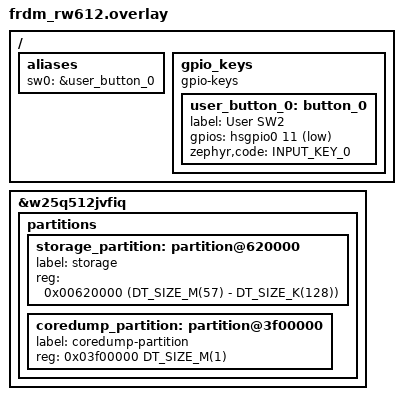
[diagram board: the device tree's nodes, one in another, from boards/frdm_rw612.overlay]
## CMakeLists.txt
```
cmake_minimum_required(VERSION 3.20.0)

# Board overlays use Zephyr 4.4 layouts; extend them for Zephyr 4.5 and newer.
find_package(Zephyr REQUIRED HINTS $ENV{ZEPHYR_BASE} COMPONENTS version)
if (KERNEL_VERSION_STRING VERSION_GREATER_EQUAL "4.5.0")
  set(coredump_board "${BOARD}")
  if (NOT coredump_board)
    set(coredump_board "$ENV{BOARD}")
  endif ()
  string(REGEX REPLACE "@[^/]*" "" coredump_board "${coredump_board}")
  string(REPLACE "/" "_" coredump_board "${coredump_board}")
  set(coredump_partition_overlay
      "${CMAKE_CURRENT_SOURCE_DIR}/boards/zephyr-4.5/${coredump_board}.overlay")
  if (EXISTS "${coredump_partition_overlay}")
    list(APPEND EXTRA_DTC_OVERLAY_FILE "${coredump_partition_overlay}")
  endif ()
endif ()

find_package(Zephyr REQUIRED HINTS $ENV{ZEPHYR_BASE})
project(spotflow_ble)

target_sources(app PRIVATE src/main.c)
```

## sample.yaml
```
sample:
  name: Spotflow BLE sample
tests:
  sample.spotflow.ble:
    integration_platforms:
      - siwx917_dk2605a
    platform_allow:
      - siwx917_dk2605a
    tags:
      - bluetooth
      - spotflow
    harness: bluetooth
```

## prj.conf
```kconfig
CONFIG_SPOTFLOW=y
CONFIG_SPOTFLOW_TRANSPORT_BLE=y
CONFIG_SPOTFLOW_COREDUMPS=y
CONFIG_SPOTFLOW_LOG_BACKEND=y
CONFIG_SPOTFLOW_METRICS=y
CONFIG_SPOTFLOW_METRICS_HEARTBEAT_INTERVAL=10
CONFIG_SPOTFLOW_METRICS_SYSTEM=y
# limit the the number of threads to avoid overloading the ble transport with
# metric with too many dimensions
CONFIG_SPOTFLOW_METRICS_SYSTEM_STACK_MAX_THREADS=16

CONFIG_BT=y
CONFIG_BT_PERIPHERAL=y
CONFIG_BT_DEVICE_NAME="Spotflow BLE device"
CONFIG_BT_DEVICE_APPEARANCE=0

CONFIG_GPIO=y

CONFIG_SPOTFLOW_DEVICE_ID="testing_device"

CONFIG_LOG=y
CONFIG_LOG_DEFAULT_LEVEL=3
CONFIG_LOG_BACKEND_UART=y
CONFIG_LOG_MAX_LEVEL=4
CONFIG_PRINTK=y
CONFIG_CONSOLE=y
CONFIG_UART_CONSOLE=y
CONFIG_MAIN_STACK_SIZE=2048
```

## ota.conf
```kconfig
# Add with EXTRA_CONF_FILE for OTA-capable boards. Keep the default BLE sample
# usable on devices without persistent storage or firmware-update support.
CONFIG_SPOTFLOW_OTA=y
# Demonstration only: an unattended browser test can connect without pairing.
# Production OTA enables encryption by default; configure trusted pairing there.
CONFIG_SPOTFLOW_BLE_REQUIRE_ENCRYPTION=n
CONFIG_SETTINGS=y
CONFIG_NVS=y
CONFIG_SETTINGS_NVS=y
```

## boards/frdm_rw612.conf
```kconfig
CONFIG_BT_DEVICE_NAME="Spotflow NXP"
CONFIG_SPOTFLOW_DEVICE_ID="testing_device_nxp"

CONFIG_DEBUG_COREDUMP_THREADS_METADATA=y
CONFIG_DEBUG_COREDUMP_MEMORY_DUMP_THREADS=y
```

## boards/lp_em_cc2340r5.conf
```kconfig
# CC2340R5 has only 36 KiB of SRAM, so this board uses the BLE transport with
# deliberately small queues and buffers. Keep the generic prj.conf useful for
# larger boards and put the CC2340R5 tradeoffs here.

# This sample uses logs, and coredumps with tightly bounded buffers.
# Metrics can be enabled if the application needs them, but they are disabled by default to
# save RAM. The sample does not use Spotflow Settings, so the default is disabled.

CONFIG_BT_DEVICE_NAME="Spotflow Texas Instruments"
CONFIG_SPOTFLOW_DEVICE_ID="ti_cc2340r5"

# This sample does not add session labels. The run ID and build ID fit in the
# minimum BLE metadata workspace.
CONFIG_SPOTFLOW_SESSION_METADATA_BUFFER_SIZE=64

# The common sample already enables Spotflow BLE logging. Keep these explicit so
# this board profile remains self-contained if prj.conf changes later.
CONFIG_SPOTFLOW=y
CONFIG_SPOTFLOW_TRANSPORT_BLE=y
CONFIG_SPOTFLOW_LOG_BACKEND=y
CONFIG_SPOTFLOW_COREDUMPS=y

# The TI CC23x0 downstream SoC reboot hook does not implement SYS_REBOOT_COLD.
# Use warm reboot so coredump-triggered fatal errors reset instead of spinning.
CONFIG_SPOTFLOW_COREDUMPS_REBOOT_WARM=y

# Enable the metrics supported by this BLE-only target. Network metrics require
# Zephyr networking, and this TI downstream does not provide CPU_LOAD.
CONFIG_SPOTFLOW_METRICS=n
# CONFIG_SPOTFLOW_METRICS=y
# CONFIG_SPOTFLOW_METRICS_SYSTEM=y
# CONFIG_SPOTFLOW_METRICS_SYSTEM_HEAP=y
# CONFIG_SPOTFLOW_METRICS_SYSTEM_NETWORK=n
# CONFIG_SPOTFLOW_METRICS_SYSTEM_CPU=n
# CONFIG_SPOTFLOW_METRICS_SYSTEM_CONNECTION=y
# CONFIG_SPOTFLOW_METRICS_SYSTEM_RESET_CAUSE=y
# CONFIG_SPOTFLOW_METRICS_SYSTEM_STACK=y
# CONFIG_SPOTFLOW_METRICS_SYSTEM_STACK_ALL_THREADS=n
# CONFIG_SPOTFLOW_METRICS_SYSTEM_STACK_MAX_THREADS=2
# CONFIG_SPOTFLOW_METRICS_SYSTEM_COLLECTION_INTERVAL=30
# CONFIG_SPOTFLOW_METRICS_SYSTEM_AGGREGATION_INTERVAL=60

# Six system metrics, the sample counter, battery level, and accelerometer
# magnitude exactly fill the registry. All current metric names, including their
# terminators, fit in 32 bytes.
# CONFIG_SPOTFLOW_METRICS_MAX_REGISTERED=10
# CONFIG_SPOTFLOW_METRICS_MAX_NAME_LENGTH=32
# CONFIG_SPOTFLOW_METRICS_MAX_LABELS_PER_METRIC=1
# CONFIG_SPOTFLOW_METRICS_QUEUE_SIZE=4
# CONFIG_SPOTFLOW_METRICS_CBOR_BUFFER_SIZE=256
# CONFIG_SPOTFLOW_METRICS_HEARTBEAT=y
# CONFIG_SPOTFLOW_METRICS_HEARTBEAT_INTERVAL=60
# CONFIG_HEAP_MEM_POOL_ADD_SIZE_SPOTFLOW_METRICS=4096
# CONFIG_HEAP_MEM_POOL_ADD_SIZE_SPOTFLOW_METRICS_SYSTEM=8192

# Persisted cloud configuration remains disabled; Settings/NVS needs its own
# storage budget.
CONFIG_SPOTFLOW_SETTINGS=n

# Spotflow BLE session metadata and coredump IDs use sys_rand32_get(). The board
# disables entropy by default, so enable the CC23x0 entropy source here.
CONFIG_ENTROPY_GENERATOR=y

# This BLE-only sample does not need TLS. The board default enables MbedTLS, but
# TinyCrypt is already present through Bluetooth and is enough for CTR-DRBG.
CONFIG_MBEDTLS=n
CONFIG_CTR_DRBG_CSPRNG_GENERATOR=y

# The CC23x0 entropy driver allocates the radio-noise buffer from the system heap
# during startup. 256 words is the driver-enforced minimum and 64 bytes is enough
# to seed CTR-DRBG for this sample. Increase back to 512/128 if more subsystems
# start consuming raw entropy directly.
CONFIG_ENTROPY_CC23X0_NOISE_INPUT_WORD_LENGTH=256
CONFIG_ENTROPY_CC23X0_ENTROPY_BYTE_LENGTH=64

# The entropy driver's hidden heap minimum is fixed at 3072 bytes even when the
# noise buffer is reduced. Right-size the shared system heap explicitly: enough
# for the 1024-byte startup entropy allocation plus Spotflow's small runtime
# queues. Increase this first if k_malloc failures appear.
CONFIG_HEAP_MEM_POOL_SIZE=4096
CONFIG_HEAP_MEM_POOL_IGNORE_MIN=y

# The Bluetooth host PRNG pulls in extra TinyCrypt HMAC/SHA state. With SMP,
# privacy and bonding disabled, Zephyr's CTR-DRBG-backed random API is enough.
CONFIG_BT_HOST_CRYPTO_PRNG=n

# Keep UART logs for bring-up/debugging. Spotflow still sends logs over BLE; the
# UART backend only adds local visibility. If RAM becomes critical, reduce log
# levels or buffers before disabling UART.
CONFIG_LOG_BACKEND_UART=y
CONFIG_LOG_MODE_DEFERRED=y
CONFIG_LOG_DEFAULT_LEVEL=3
CONFIG_LOG_MAX_LEVEL=3
CONFIG_LOG_BUFFER_SIZE=256
CONFIG_LOG_PROCESS_THREAD_STACK_SIZE=640

# The sample main thread configures GPIO, reports one metric, and emits logs. A
# separate 640-byte thread reports generated battery and accelerometer metrics.
CONFIG_MAIN_STACK_SIZE=896

# The Spotflow processor only runs BLE framing and queue draining, not TLS.
CONFIG_SPOTFLOW_PROCESSING_THREAD_STACK_SIZE=1152

# Two queued Spotflow log messages is enough to absorb short bursts while keeping
# heap usage bounded. Increase to 4 if normal operation drops logs; decrease to 1
# only if occasional log loss is acceptable and RAM is still tight.
CONFIG_SPOTFLOW_LOG_BACKEND_QUEUE_SIZE=2
CONFIG_HEAP_MEM_POOL_ADD_SIZE_SPOTFLOW_LOGGING=512

# Keep individual log records small. The sample still sends normal short logs,
# but long lines are dropped/truncated by Spotflow rather than consuming RAM.
# 96/192 can be lowered to 64/160 for very short messages, or raised to 128/256
# if real application messages need it.
CONFIG_SPOTFLOW_LOG_BUFFER_SIZE=96
CONFIG_SPOTFLOW_CBOR_LOG_MAX_LEN=192
CONFIG_SPOTFLOW_LOG_INCLUDE_BODY_TEMPLATE=n

# Send INFO/WARNING/ERROR records to Spotflow by default. Set to 2 to send only
# warnings/errors if BLE throughput or heap pressure becomes a problem.
CONFIG_SPOTFLOW_DEFAULT_SENT_LOG_LEVEL=3
CONFIG_SPOTFLOW_MODULE_DEFAULT_LOG_LEVEL=2
CONFIG_SPOTFLOW_LOGS_PROCESSING_LOG_LEVEL=2
CONFIG_SPOTFLOW_COREDUMPS_PROCESSING_LOG_LEVEL=2

# Full RAM dumps do not fit comfortably on this device. Minimal coredumps keep
# the fault context and current stack only, which fits the small flash partition
# and is the practical option for this board.
CONFIG_DEBUG_COREDUMP_MEMORY_DUMP_MIN=y
CONFIG_SPOTFLOW_COREDUMPS_THREAD_STACK_SIZE=640

# 128-byte chunks minimize heap and static RAM. Upload is slower because BLE has
# more fragments, but reliability on 36 KiB SRAM is better than using 512/1024.
CONFIG_SPOTFLOW_COREDUMPS_CHUNK_SIZE=128
CONFIG_SPOTFLOW_COREDUMPS_BACKEND_QUEUE_SIZE=1
CONFIG_HEAP_MEM_POOL_ADD_SIZE_SPOTFLOW_COREDUMPS=512

# Use the minimum ATT MTU and ACL buffer sizes. Spotflow BLE framing fragments
# larger CBOR messages, so this saves RAM at the cost of throughput.
CONFIG_BT_L2CAP_TX_MTU=23
CONFIG_BT_BUF_ACL_TX_SIZE=27
CONFIG_BT_BUF_ACL_RX_SIZE=27
CONFIG_BT_BUF_ACL_TX_COUNT=3
CONFIG_BT_BUF_ACL_RX_COUNT=2
CONFIG_BT_L2CAP_TX_BUF_COUNT=3
CONFIG_BT_ATT_TX_COUNT=3
CONFIG_BT_CONN_TX_MAX=3

# Trim Bluetooth host features that are not needed by the Spotflow GATT service.
# Re-enable SMP/privacy/settings only if the gateway requires pairing/bonding.
CONFIG_BT_SMP=n
CONFIG_BT_GATT_SERVICE_CHANGED=n
CONFIG_BT_GATT_CACHING=n
CONFIG_BT_PHY_UPDATE=n
CONFIG_BT_DATA_LEN_UPDATE=n

# Keep HCI event/command buffers near their documented minimums. EVT count 3 is
# a small safety margin over the minimum 2; reducing to 2 is possible if measured.
CONFIG_BT_BUF_EVT_RX_SIZE=68
CONFIG_BT_BUF_EVT_RX_COUNT=3
CONFIG_BT_BUF_EVT_DISCARDABLE_COUNT=1
CONFIG_BT_BUF_CMD_TX_SIZE=65

# Enable stack measurement helpers while validating this tight RAM profile. They
# can be disabled for production if the extra diagnostics are not wanted.
CONFIG_THREAD_NAME=y
CONFIG_INIT_STACKS=y
CONFIG_STACK_SENTINEL=y
CONFIG_STACK_USAGE=y

# TI runs Bluetooth RX callbacks on sysworkq and recommends at least 1200 bytes.
CONFIG_SYSTEM_WORKQUEUE_STACK_SIZE=1280
CONFIG_ISR_STACK_SIZE=1536
```

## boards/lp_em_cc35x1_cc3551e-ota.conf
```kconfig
CONFIG_CC35XXE_FWU=y
CONFIG_CC35XXE_GENERATE_FLASH_MAP_CONFIG=y
CONFIG_CC35XXE_FLASH_PROFILE_IS25WJ032F=y
CONFIG_CC35XXE_VENDOR_IMAGE_VERSION="0.0.1.0"
CONFIG_SPOTFLOW_OTA_AUTO_HANDLE_MAIN_FIRMWARE=y
CONFIG_SPOTFLOW_OTA_MAIN_FIRMWARE_PSA_FWU=y
CONFIG_MBEDTLS_PSA_CRYPTO_EXTERNAL_RNG=y
CONFIG_CRYPTO=y
CONFIG_CRYPTO_TI_CC35XX=y
# Keep the legacy EC entry points used by TI's radio library when SMP is enabled.
CONFIG_MBEDTLS_PSA_P256M_DRIVER_ENABLED=n
```

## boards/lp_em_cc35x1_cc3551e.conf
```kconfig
CONFIG_BT_DEVICE_NAME="Spotflow Texas Instruments"
CONFIG_SPOTFLOW_DEVICE_ID="ti_cc35x1_cc3551e"

# TI's combined CC35x1 radio driver routes Bluetooth through the Wi-Fi host
# stack, whose Kconfig selections require Zephyr networking to be enabled.
CONFIG_NETWORKING=y
CONFIG_NET_L2_ETHERNET=y

# Absorb bursts from the CC35x1 driver without exhausting Zephyr's RX pools.
CONFIG_NET_PKT_RX_COUNT=32
CONFIG_NET_BUF_RX_COUNT=64

# Matches TI's CC35x1 Bluetooth peripheral reference configuration:
# zephyr/samples/bluetooth/peripheral/boards/lp_em_cc35x1_cc3551e.conf
CONFIG_BT_GATT_CACHING=n
CONFIG_BT_PHY_UPDATE=n
CONFIG_HEAP_MEM_POOL_SIZE=81920
CONFIG_MAIN_STACK_SIZE=61440
CONFIG_NET_TX_STACK_SIZE=2048
CONFIG_NET_RX_STACK_SIZE=2048
CONFIG_DYNAMIC_THREAD_POOL_SIZE=3
CONFIG_DYNAMIC_THREAD_STACK_SIZE=8192

# A full 1 MiB RAM dump cannot fit in the board's application storage area.
CONFIG_DEBUG_COREDUMP_MEMORY_DUMP_MIN=y
```

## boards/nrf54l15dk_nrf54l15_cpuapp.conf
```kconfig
CONFIG_BT_DEVICE_NAME="Spotflow nRF54L15"
CONFIG_SPOTFLOW_DEVICE_ID="testing_device_nrf54l15"

# Keep logs and metrics in RRAM while no gateway is connected
CONFIG_SPOTFLOW_PERSISTENT_BUFFER=y
# FCB needs write blocks of at most 8 bytes; with the RRAMC write buffer disabled, RRAM accepts
# 32-bit writes (see write-block-size in nrf54l15dk_nrf54l15_cpuapp.overlay)
CONFIG_NRF_RRAM_WRITE_BUFFER_SIZE=0

CONFIG_DEBUG_COREDUMP_THREADS_METADATA=y
CONFIG_DEBUG_COREDUMP_MEMORY_DUMP_THREADS=y
```

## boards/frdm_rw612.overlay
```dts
 /* GPIO not available in 4.1.0, adding based on commit
 * https://github.com/zephyrproject-rtos/zephyr/commit/2df6b7fd2dea95105b3598c41fecbd7089fab080
 */
#include <zephyr/dt-bindings/input/input-event-codes.h>
/ {
	aliases {
		/* make an alias so we can refer to "sw0" in code */
		sw0 = &user_button_0;
	};

	gpio_keys {
		compatible = "gpio-keys";

		user_button_0: button_0 {
			label = "User SW2";
			gpios = <&hsgpio0 11 (GPIO_ACTIVE_LOW | GPIO_PULL_UP)>;
			zephyr,code = <INPUT_KEY_0>;
			status = "okay";
		};
	};
};

/* External flash chip - Winbond */
&w25q512jvfiq {
	partitions {
		/* Reducing size by 1 MB to leave space for coredump */
		storage_partition: partition@620000 {
			label = "storage";
			reg = <0x00620000 (DT_SIZE_M(57) - DT_SIZE_K(128))>;
		};

		/* Last 1MB of 64 MB flash */
		coredump_partition: partition@3f00000 {
			label = "coredump-partition";
			reg = <0x03f00000 DT_SIZE_M(1)>;
		};
	};
};
```

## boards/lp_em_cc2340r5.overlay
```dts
/delete-node/ &storage_partition;

&flash0 {
	partitions {
		/* Keep the board's MCUboot/dual-slot OTA layout. Split the original
		 * 16 KiB storage partition into 4 KiB storage and 12 KiB coredump.
		 */
		storage_partition: partition@7c000 {
			label = "storage";
			reg = <0x0007c000 0x00001000>;
		};

		/* 12 KiB is intended for DEBUG_COREDUMP_MEMORY_DUMP_MIN. A full RAM
		 * coredump would need a larger partition and is not practical here.
		 */
		coredump_partition: partition@7d000 {
			label = "coredump-partition";
			reg = <0x0007d000 0x00003000>;
		};
	};
};
```

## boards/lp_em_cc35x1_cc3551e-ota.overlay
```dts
/* Use the same factory layout for Wi-Fi and BLE OTA images. */
#include "../../ota_psa/boards/lp_em_cc35x1_cc3551e.overlay"

&storage_partition {
	reg = <0x8000 0x8000>;
};

&flash2 {
	partitions {
		coredump_partition: partition@10000 {
			label = "coredump-partition";
			reg = <0x10000 0x12000>;
		};
	};
};
```

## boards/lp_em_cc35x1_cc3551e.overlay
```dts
/delete-node/ &storage_partition;

&wlan0 {
	status = "okay";
};

&hci0 {
	status = "okay";
};

&flash2 {
	partitions {
		coredump_partition: partition@c000 {
			label = "coredump-partition";
			reg = <0x0000c000 0x0001f000>;
		};
	};
};
```

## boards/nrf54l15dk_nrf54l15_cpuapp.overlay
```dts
/* The sample does not use MCUboot, so the second image slot is free. Shrink it by 128 KiB and
 * place the Spotflow persistent buffer and the core dump partition right before the storage
 * partition.
 */
&slot1_partition {
	reg = <0xc2000 DT_SIZE_K(584)>;
};

/* The persistent buffer uses Zephyr FCB, which supports write blocks of at most 8 bytes. RRAM
 * defaults to 16-byte lines because of the RRAMC write buffer, so the buffer is disabled in
 * nrf54l15dk_nrf54l15_cpuapp.conf (CONFIG_NRF_RRAM_WRITE_BUFFER_SIZE=0) and RRAM is written in
 * 32-bit words.
 */
&cpuapp_rram {
	write-block-size = <4>;

	partitions {
		/* 16 sectors of 4 KiB */
		spotflow_buffer_partition: partition@154000 {
			compatible = "zephyr,mapped-partition";
			label = "spotflow-buffer";
			reg = <0x154000 DT_SIZE_K(64)>;
		};

		coredump_partition: partition@164000 {
			compatible = "zephyr,mapped-partition";
			label = "coredump-partition";
			reg = <0x164000 DT_SIZE_K(64)>;
		};
	};
};
```

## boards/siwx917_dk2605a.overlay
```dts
/* Reserve the last 1 MiB of the OTA swap area for Zephyr coredumps. */

&ota_swap_partition {
	reg = <0x400000 0x2cf000>;
};

&flash0 {
	partitions {
		coredump_partition: partition@6cf000 {
			label = "coredump-partition";
			reg = <0x6cf000 0x100000>;
		};
	};
};
```

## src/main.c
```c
#ifdef CONFIG_SPOTFLOW_OTA_AUTO_HANDLE_MAIN_FIRMWARE
#include <spotflow/ota.h>
#ifdef CONFIG_SPOTFLOW_OTA_PSA_FWU_TI_CC35XX
#include <psa_fwu.h>
#endif /* CONFIG_SPOTFLOW_OTA_PSA_FWU_TI_CC35XX */
#endif /* CONFIG_SPOTFLOW_OTA_AUTO_HANDLE_MAIN_FIRMWARE */

#include <zephyr/drivers/gpio.h>
#include <zephyr/kernel.h>
#include <zephyr/logging/log.h>
#include <zephyr/random/random.h>

#include <stdbool.h>
#include <stdint.h>

#ifdef CONFIG_SPOTFLOW_METRICS
#include "metrics/spotflow_metrics_backend.h"
#include "metrics/spotflow_metrics_registry.h"
#endif

#if defined(CONFIG_SPOTFLOW_METRICS_SYSTEM_STACK) && \
	!defined(CONFIG_SPOTFLOW_METRICS_SYSTEM_STACK_ALL_THREADS)
#include "metrics/system/spotflow_metrics_system.h"
#endif

LOG_MODULE_REGISTER(spotflow_ble_sample, LOG_LEVEL_INF);

#define SW0_NODE DT_ALIAS(sw0)
#define BUTTON_POLL_INTERVAL K_MSEC(50)
#define BUTTON_PRESSED_STATE 1
#define TELEMETRY_THREAD_STACK_SIZE 640
#define TELEMETRY_THREAD_PRIORITY 5
#define TELEMETRY_REPORT_INTERVAL K_SECONDS(10)

/* compatibility macro for older Zephyr versions */
#ifndef DT_NODE_HAS_STATUS_OKAY
#define DT_NODE_HAS_STATUS_OKAY(node_id) DT_NODE_HAS_STATUS(node_id, okay)
#endif

#if !DT_NODE_HAS_STATUS_OKAY(SW0_NODE)
#error "Unsupported board: sw0 devicetree alias is not defined"
#endif

#ifndef CONFIG_SOC_CC2340R5
static const char* const long_warning_message =
	"framing-test payload: abcdefghijklmnopqrstuvwxyz 0123456789 "
	"abcdefghijklmnopqrstuvwxyz 0123456789 abcdefghijklmnopqrstuvwxyz 0123456789 "
	"abcdefghijklmnopqrstuvwxyz 0123456789 abcdefghijklmnopqrstuvwxyz 0123456789 "
	"abcdefghijklmnopqrstuvwxyz 0123456789 abcdefghijklmnopqrstuvwxyz 0123456789";
#else
/* CC2340R5 is configured with a smaller log buffer */
static const char* const long_warning_message =
	"framing-test payload: abcdefghijklmnopqrstuvwxyz 0123456789 ";
#endif

static const struct gpio_dt_spec button = GPIO_DT_SPEC_GET_OR(SW0_NODE, gpios, { 0 });

#ifdef CONFIG_SPOTFLOW_METRICS
static struct spotflow_metric_int* sample_counter_metric;
static struct spotflow_metric_int* battery_level_metric;
static struct spotflow_metric_float* accelerometer_magnitude_metric;

static void telemetry_thread_entry(void* arg1, void* arg2, void* arg3);

K_THREAD_DEFINE(telemetry_thread, TELEMETRY_THREAD_STACK_SIZE, telemetry_thread_entry, NULL, NULL,
		NULL, TELEMETRY_THREAD_PRIORITY, 0, 0);
#endif

static struct gpio_callback button_cb_data;

#if defined(CONFIG_SPOTFLOW_METRICS_SYSTEM_STACK) && \
	!defined(CONFIG_SPOTFLOW_METRICS_SYSTEM_STACK_ALL_THREADS)
static void enable_thread_stack_metric(void)
{
	for (int attempt = 0; attempt < 20; ++attempt) {
		int rc = spotflow_metrics_system_enable_thread_stack(NULL);
		if (rc == 0 || rc == -EEXIST) {
			return;
		}
		if (rc != -EINVAL) {
			LOG_WRN("Failed to enable main stack metric: %d", rc);
			return;
		}
		k_sleep(K_MSEC(100));
	}

	LOG_WRN("System stack metrics were not ready");
}
#endif

#ifdef CONFIG_SPOTFLOW_METRICS
static void telemetry_thread_entry(void* arg1, void* arg2, void* arg3)
{
	int battery_level_percent = 100;

	ARG_UNUSED(arg1);
	ARG_UNUSED(arg2);
	ARG_UNUSED(arg3);

	int rc = spotflow_register_metric_int("battery_level_percent", SPOTFLOW_AGG_INTERVAL_NONE,
					      &battery_level_metric);
	if (rc < 0) {
		LOG_ERR("Failed to register battery level metric: %d", rc);
	}

	rc = spotflow_register_metric_float("accelerometer_magnitude_g", SPOTFLOW_AGG_INTERVAL_NONE,
					    &accelerometer_magnitude_metric);
	if (rc < 0) {
		LOG_ERR("Failed to register accelerometer magnitude metric: %d", rc);
	}
#if defined(CONFIG_SPOTFLOW_METRICS_SYSTEM_STACK) && \
	!defined(CONFIG_SPOTFLOW_METRICS_SYSTEM_STACK_ALL_THREADS)
	enable_thread_stack_metric();
#endif

	while (true) {
		if (battery_level_metric != NULL) {
			rc = spotflow_report_metric_int(battery_level_metric,
							battery_level_percent);
			if (rc < 0) {
				LOG_WRN("Failed to report battery level metric: %d", rc);
			}
		}

		if (accelerometer_magnitude_metric != NULL) {
			double magnitude_g = (double)(sys_rand32_get() % 201U) / 100.0;

			rc = spotflow_report_metric_float(accelerometer_magnitude_metric,
							  magnitude_g);
			if (rc < 0) {
				LOG_WRN("Failed to report accelerometer magnitude metric: %d", rc);
			}
		}

		battery_level_percent =
			battery_level_percent == 0 ? 100 : battery_level_percent - 1;
		k_sleep(TELEMETRY_REPORT_INTERVAL);
	}
}
#endif

static void button_pressed(void)
{
	LOG_INF("Button pressed. Going to oops.");
	k_oops();
}

static void button_callback(const struct device* dev, struct gpio_callback* cb, uint32_t pins)
{
	ARG_UNUSED(dev);
	ARG_UNUSED(cb);
	ARG_UNUSED(pins);

	button_pressed();
}

static int prepare_button(void)
{
	if (!gpio_is_ready_dt(&button)) {
		LOG_ERR("Error: button device %s is not ready", button.port->name);
		return -EINVAL;
	}

	int rc = gpio_pin_configure_dt(&button, GPIO_INPUT);
	if (rc != 0) {
		LOG_ERR("Error %d: failed to configure %s pin %d", rc, button.port->name,
			button.pin);
		return rc;
	}
	rc = gpio_pin_interrupt_configure_dt(&button, GPIO_INT_EDGE_TO_ACTIVE);
	if (rc != 0) {
		LOG_ERR("Error %d: failed to configure interrupt on %s pin %d", rc,
			button.port->name, button.pin);
		return rc;
	}

	gpio_init_callback(&button_cb_data, button_callback, BIT(button.pin));
	rc = gpio_add_callback(button.port, &button_cb_data);
	if (rc != 0) {
		LOG_ERR("Error %d: failed to add button callback", rc);
		return rc;
	}

	LOG_INF("Set up interrupt button at %s pin %d", button.port->name, button.pin);
	return 0;
}

int main(void)
{
#ifdef CONFIG_SPOTFLOW_OTA_AUTO_HANDLE_MAIN_FIRMWARE
	/* Demonstration only: production applications must first run their health
	 * checks before accepting an unconfirmed image.
	 */
	struct spotflow_ota_main_firmware_state firmware_state;
	if (spotflow_get_main_firmware_update_state(&firmware_state) == 0 &&
	    firmware_state.phase == SPOTFLOW_OTA_PHASE_UNCONFIRMED) {
		int confirm_rc = spotflow_confirm_main_firmware_image(&firmware_state);
		if (confirm_rc != 0) {
			LOG_ERR("Failed to confirm firmware: %d", confirm_rc);
		}
#ifdef CONFIG_SPOTFLOW_OTA_PSA_FWU_TI_CC35XX
		else if (firmware_state.phase == SPOTFLOW_OTA_PHASE_UNCONFIRMED) {
			(void)psa_fwu_request_reboot();
		}
#endif /* CONFIG_SPOTFLOW_OTA_PSA_FWU_TI_CC35XX */
	}
#endif /* CONFIG_SPOTFLOW_OTA_AUTO_HANDLE_MAIN_FIRMWARE */
	uint32_t log_counter = 0;
#ifdef CONFIG_SPOTFLOW_METRICS
	int metric_rc = spotflow_register_metric_int("sample_counter", SPOTFLOW_AGG_INTERVAL_NONE,
						     &sample_counter_metric);
	if (metric_rc < 0) {
		LOG_ERR("Failed to register sample metric: %d", metric_rc);
	} else {
		LOG_INF("Registered sample metric");
	}
#endif
	int rc;

	LOG_INF("Starting Spotflow BLE sample");
	LOG_INF("Press button to trigger a coredump that will be sent over BLE after reboot.");

	rc = prepare_button();
	if (rc != 0) {
		LOG_ERR("Failed to prepare button, exiting");
		return rc;
	}

#if defined(CONFIG_SPOTFLOW_METRICS_SYSTEM_STACK) && \
	!defined(CONFIG_SPOTFLOW_METRICS_SYSTEM_STACK_ALL_THREADS)
	enable_thread_stack_metric();
#endif

	while (true) {
		log_counter++;

#ifdef CONFIG_SPOTFLOW_METRICS
		if (sample_counter_metric != NULL) {
			rc = spotflow_report_metric_int(sample_counter_metric, log_counter);
			if (rc < 0) {
				LOG_WRN("Failed to report sample metric: %d", rc);
			}
		}
#endif

		if ((log_counter % 10U) == 0U) {
			LOG_WRN("Spotflow BLE framing test %u: %s", log_counter,
				long_warning_message);
		} else {
			LOG_INF("Hello from Zephyr to Spotflow BLE: %u", log_counter);
		}
		k_sleep(K_SECONDS(1));
	}

	return 0;
}
```
